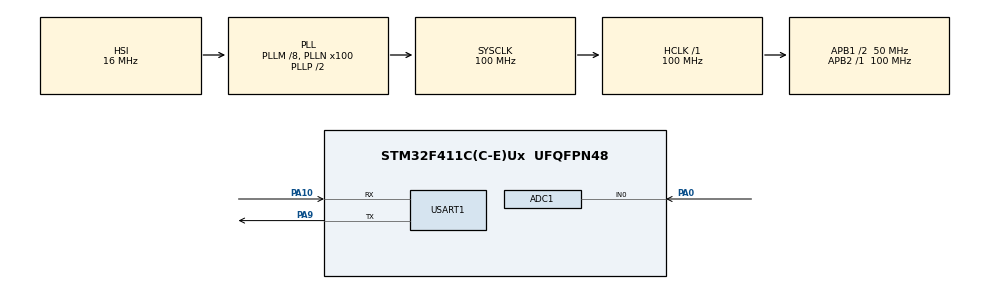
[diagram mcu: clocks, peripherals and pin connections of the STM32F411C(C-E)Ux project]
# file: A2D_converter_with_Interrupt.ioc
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ADC1.Channel-0\#ChannelRegularConversion=ADC_CHANNEL_0
ADC1.ContinuousConvMode=DISABLE
ADC1.ExternalTrigConv=ADC_EXTERNALTRIGCONV_T1_CC1
ADC1.NbrOfConversion=1
ADC1.NbrOfConversionFlag=1
ADC1.Rank-0\#ChannelRegularConversion=1
ADC1.SamplingTime-0\#ChannelRegularConversion=ADC_SAMPLETIME_3CYCLES
ADC1.master=1
Mcu.Family=STM32F4
Mcu.Name=STM32F411C(C-E)Ux
Mcu.Package=UFQFPN48
NVIC.ADC_IRQn=true\:0\:0\:false\:false\:true\:true\:true\:true
NVIC.PriorityGroup=NVIC_PRIORITYGROUP_4
PA0-WKUP.Signal=ADCx_IN0
PA10.Mode=Asynchronous
PA10.Signal=USART1_RX
PA9.Mode=Asynchronous
PA9.Signal=USART1_TX
PH0\ -\ OSC_IN.Mode=HSE-External-Oscillator
PH0\ -\ OSC_IN.Signal=RCC_OSC_IN
PH1\ -\ OSC_OUT.Mode=HSE-External-Oscillator
PH1\ -\ OSC_OUT.Signal=RCC_OSC_OUT
ProjectManager.HeapSize=0x200
ProjectManager.StackSize=0x400
ProjectManager.TargetToolchain=STM32CubeIDE
RCC.48MHZClocksFreq_Value=50000000
RCC.AHBFreq_Value=100000000
RCC.APB1CLKDivider=RCC_HCLK_DIV2
RCC.APB1Freq_Value=50000000
RCC.APB1TimFreq_Value=100000000
RCC.APB2Freq_Value=100000000
RCC.APB2TimFreq_Value=100000000
RCC.CortexFreq_Value=100000000
RCC.HCLKFreq_Value=100000000
RCC.HSE_VALUE=25000000
RCC.HSI_VALUE=16000000
RCC.LSE_VALUE=32768
RCC.PLLM=8
RCC.PLLN=100
RCC.RCC_TIM_PRescaler_Selection=RCC_TIMPRES_DESACTIVATED
RCC.SYSCLKFreq_VALUE=100000000
RCC.SYSCLKSource=RCC_SYSCLKSOURCE_PLLCLK
RCC.VCOOutputFreq_Value=200000000
SH.ADCx_IN0.0=ADC1_IN0,IN0
TIM9.Channel-Output\ Compare1\ No\ Output=TIM_CHANNEL_1
USART1.VirtualMode=VM_ASYNC
VP_TIM9_VS_ClockSourceINT.Mode=Internal
VP_TIM9_VS_no_output1.Mode=Output Compare1 No Output
board=custom

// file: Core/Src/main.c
/* USER CODE BEGIN Header */
/**
  ******************************************************************************
  * @file           : main.c
  * @brief          : Main program body
  ******************************************************************************
  * @attention
  *
  * Copyright (c) 2023 STMicroelectronics.
  * All rights reserved.
  *
  * This software is licensed under terms that can be found in the LICENSE file
  * in the root directory of this software component.
  * If no LICENSE file comes with this software, it is provided AS-IS.
  *
  ******************************************************************************
  */
/* USER CODE END Header */
#include "main.h"

ADC_HandleTypeDef hadc1;

TIM_HandleTypeDef htim9;

UART_HandleTypeDef huart1;

/* USER CODE BEGIN PV */
char txbuf[25];
uint16_t adc_result;
char adc_valid;

/* USER CODE END PV */

void SystemClock_Config(void);
static void MX_GPIO_Init(void);
static void MX_ADC1_Init(void);
static void MX_USART1_UART_Init(void);
static void MX_TIM9_Init(void);

int main(void)
{

  /* MCU Configuration--------------------------------------------------------*/

  /* Reset of all peripherals, Initializes the Flash interface and the Systick. */
  HAL_Init();

  /* Configure the system clock */
  SystemClock_Config();

  /* Initialize all configured peripherals */
  MX_GPIO_Init();
  MX_ADC1_Init();
  MX_USART1_UART_Init();
  MX_TIM9_Init();
  /* USER CODE BEGIN 2 */
  HAL_ADC_Start_IT(&hadc1);
  /* USER CODE END 2 */

  /* Infinite loop */
  while (1)
  {
	  if(adc_valid == 1)
	  	  {
	  		sprintf (txbuf, "ADC= %d\r\n", (int)adc_result);
	  		HAL_UART_Transmit(&huart1, (uint8_t *)txbuf, strlen (txbuf), HAL_MAX_DELAY);
	  		adc_valid = 0;
	  	  }
	  HAL_Delay(100);
	  HAL_ADC_Start_IT(&hadc1);
  }
}
void HAL_ADC_ConvCpltCallback(ADC_HandleTypeDef*h)
{
	if (h == &hadc1)
	{
		adc_result = HAL_ADC_GetValue(&hadc1);
		adc_valid = 1;
	}

}
void SystemClock_Config(void)
{
  RCC_OscInitTypeDef RCC_OscInitStruct = {0};
  RCC_ClkInitTypeDef RCC_ClkInitStruct = {0};

  /** Configure the main internal regulator output voltage
  */
  __HAL_RCC_PWR_CLK_ENABLE();
  __HAL_PWR_VOLTAGESCALING_CONFIG(PWR_REGULATOR_VOLTAGE_SCALE1);

  /** Initializes the RCC Oscillators according to the specified parameters
  * in the RCC_OscInitTypeDef structure.
  */
  RCC_OscInitStruct.OscillatorType = RCC_OSCILLATORTYPE_HSI;
  RCC_OscInitStruct.HSIState = RCC_HSI_ON;
  RCC_OscInitStruct.HSICalibrationValue = RCC_HSICALIBRATION_DEFAULT;
  RCC_OscInitStruct.PLL.PLLState = RCC_PLL_ON;
  RCC_OscInitStruct.PLL.PLLSource = RCC_PLLSOURCE_HSI;
  RCC_OscInitStruct.PLL.PLLM = 8;
  RCC_OscInitStruct.PLL.PLLN = 100;
  RCC_OscInitStruct.PLL.PLLP = RCC_PLLP_DIV2;
  RCC_OscInitStruct.PLL.PLLQ = 4;
  if (HAL_RCC_OscConfig(&RCC_OscInitStruct) != HAL_OK)
  {
    Error_Handler();
  }

  /** Initializes the CPU, AHB and APB buses clocks
  */
  RCC_ClkInitStruct.ClockType = RCC_CLOCKTYPE_HCLK|RCC_CLOCKTYPE_SYSCLK
                              |RCC_CLOCKTYPE_PCLK1|RCC_CLOCKTYPE_PCLK2;
  RCC_ClkInitStruct.SYSCLKSource = RCC_SYSCLKSOURCE_PLLCLK;
  RCC_ClkInitStruct.AHBCLKDivider = RCC_SYSCLK_DIV1;
  RCC_ClkInitStruct.APB1CLKDivider = RCC_HCLK_DIV2;
  RCC_ClkInitStruct.APB2CLKDivider = RCC_HCLK_DIV1;

  if (HAL_RCC_ClockConfig(&RCC_ClkInitStruct, FLASH_LATENCY_3) != HAL_OK)
  {
    Error_Handler();
  }
}

static void MX_ADC1_Init(void)
{

  ADC_ChannelConfTypeDef sConfig = {0};

  /** Configure the global features of the ADC (Clock, Resolution, Data Alignment and number of conversion)
  */
  hadc1.Instance = ADC1;
  hadc1.Init.ClockPrescaler = ADC_CLOCK_SYNC_PCLK_DIV4;
  hadc1.Init.Resolution = ADC_RESOLUTION_12B;
  hadc1.Init.ScanConvMode = DISABLE;
  hadc1.Init.ContinuousConvMode = DISABLE;
  hadc1.Init.DiscontinuousConvMode = DISABLE;
  hadc1.Init.ExternalTrigConvEdge = ADC_EXTERNALTRIGCONVEDGE_RISING;
  hadc1.Init.ExternalTrigConv = ADC_EXTERNALTRIGCONV_T1_CC1;
  hadc1.Init.DataAlign = ADC_DATAALIGN_RIGHT;
  hadc1.Init.NbrOfConversion = 1;
  hadc1.Init.DMAContinuousRequests = DISABLE;
  hadc1.Init.EOCSelection = ADC_EOC_SINGLE_CONV;
  if (HAL_ADC_Init(&hadc1) != HAL_OK)
  {
    Error_Handler();
  }

  /** Configure for the selected ADC regular channel its corresponding rank in the sequencer and its sample time.
  */
  sConfig.Channel = ADC_CHANNEL_0;
  sConfig.Rank = 1;
  sConfig.SamplingTime = ADC_SAMPLETIME_3CYCLES;
  if (HAL_ADC_ConfigChannel(&hadc1, &sConfig) != HAL_OK)
  {
    Error_Handler();
  }

}

static void MX_TIM9_Init(void)
{

  TIM_ClockConfigTypeDef sClockSourceConfig = {0};
  TIM_OC_InitTypeDef sConfigOC = {0};

  htim9.Instance = TIM9;
  htim9.Init.Prescaler = 0;
  htim9.Init.CounterMode = TIM_COUNTERMODE_UP;
  htim9.Init.Period = 65535;
  htim9.Init.ClockDivision = TIM_CLOCKDIVISION_DIV1;
  htim9.Init.AutoReloadPreload = TIM_AUTORELOAD_PRELOAD_DISABLE;
  if (HAL_TIM_Base_Init(&htim9) != HAL_OK)
  {
    Error_Handler();
  }
  sClockSourceConfig.ClockSource = TIM_CLOCKSOURCE_INTERNAL;
  if (HAL_TIM_ConfigClockSource(&htim9, &sClockSourceConfig) != HAL_OK)
  {
    Error_Handler();
  }
  if (HAL_TIM_OC_Init(&htim9) != HAL_OK)
  {
    Error_Handler();
  }
  sConfigOC.OCMode = TIM_OCMODE_TIMING;
  sConfigOC.Pulse = 0;
  sConfigOC.OCPolarity = TIM_OCPOLARITY_HIGH;
  sConfigOC.OCFastMode = TIM_OCFAST_DISABLE;
  if (HAL_TIM_OC_ConfigChannel(&htim9, &sConfigOC, TIM_CHANNEL_1) != HAL_OK)
  {
    Error_Handler();
  }

}

static void MX_USART1_UART_Init(void)
{

  huart1.Instance = USART1;
  huart1.Init.BaudRate = 115200;
  huart1.Init.WordLength = UART_WORDLENGTH_8B;
  huart1.Init.StopBits = UART_STOPBITS_1;
  huart1.Init.Parity = UART_PARITY_NONE;
  huart1.Init.Mode = UART_MODE_TX_RX;
  huart1.Init.HwFlowCtl = UART_HWCONTROL_NONE;
  huart1.Init.OverSampling = UART_OVERSAMPLING_16;
  if (HAL_UART_Init(&huart1) != HAL_OK)
  {
    Error_Handler();
  }

}

static void MX_GPIO_Init(void)
{

  /* GPIO Ports Clock Enable */
  __HAL_RCC_GPIOH_CLK_ENABLE();
  __HAL_RCC_GPIOA_CLK_ENABLE();

}

void Error_Handler(void)
{
  __disable_irq();
  while (1)
  {
  }
}
